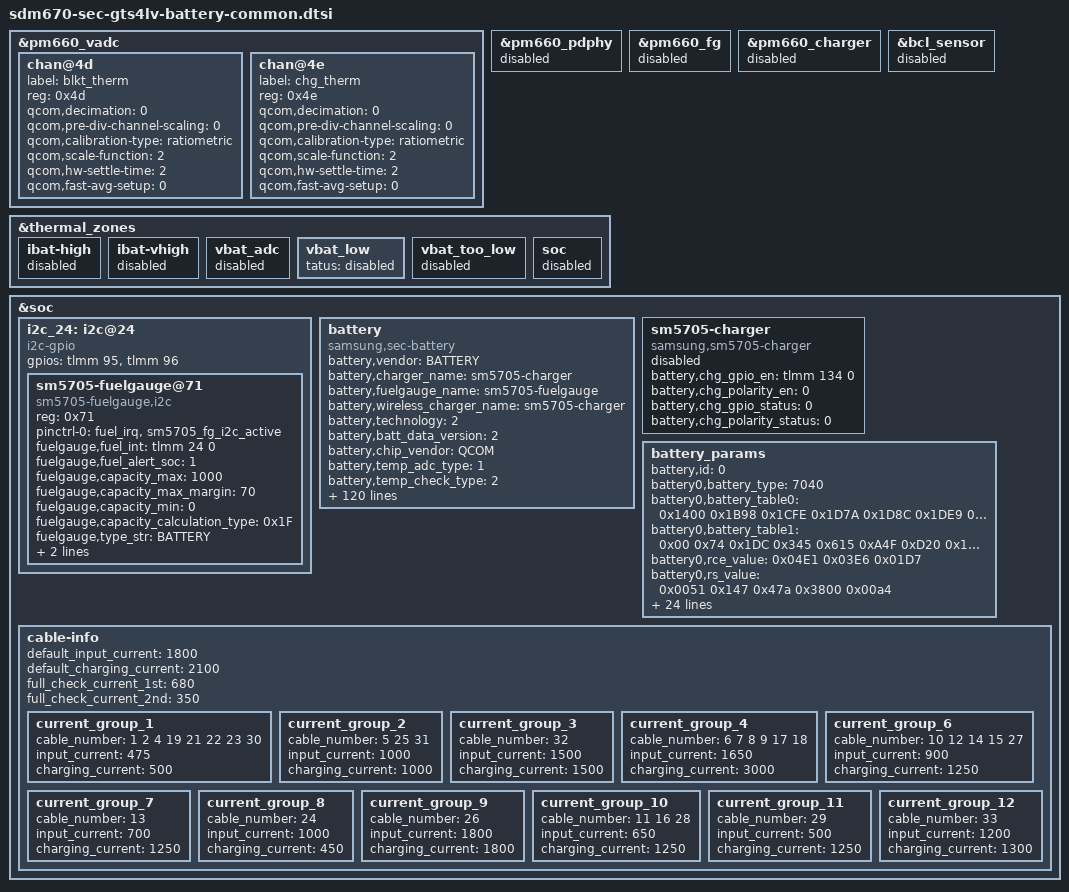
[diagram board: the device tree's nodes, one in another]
/* Copyright (c) 2014, The Linux Foundation. All rights reserved.
 *
 * This program is free software; you can redistribute it and/or modify
 * it under the terms of the GNU General Public License version 2 and
 * only version 2 as published by the Free Software Foundation.
 *
 * This program is distributed in the hope that it will be useful,
 * but WITHOUT ANY WARRANTY; without even the implied warranty of
 * MERCHANTABILITY or FITNESS FOR A PARTICULAR PURPOSE.  See the
 * GNU General Public License for more details.
 */

&pm660_vadc {
	chan@4d { /* AMUX_1 */
			label = "blkt_therm";
			reg = <0x4d>;
			qcom,decimation = <0>;
			qcom,pre-div-channel-scaling = <0>;
			qcom,calibration-type = "ratiometric";
			qcom,scale-function = <2>;
			qcom,hw-settle-time = <2>;
			qcom,fast-avg-setup = <0>;
		};

		chan@4e { /* AMUX_2 */
			label = "chg_therm";
			reg = <0x4e>;
			qcom,decimation = <0>;
			qcom,pre-div-channel-scaling = <0>;
			qcom,calibration-type = "ratiometric";
			qcom,scale-function = <2>;
			qcom,hw-settle-time = <2>;
			qcom,fast-avg-setup = <0>;
		};
};

&pm660_pdphy {
		status = "disabled";
};

&pm660_fg {
		status = "disabled";
};

&pm660_charger {
		status = "disabled";
};

&bcl_sensor{
		status = "disabled";
};

/* remove nodes related bcl */
&thermal_zones {
	ibat-high {
		status = "disabled";
	};
	ibat-vhigh {
		status = "disabled";
	};
	vbat_adc {
		status = "disabled";
	};
	vbat_low {
		tatus = "disabled";
	};
	vbat_too_low {
		status = "disabled";
	};
	soc {
		status = "disabled";
	};
};

&soc {
	i2c_24: i2c@24 {
		compatible = "i2c-gpio";
		gpios = <&tlmm 95 0 /* sda */
			&tlmm 96 0 /* scl */
			>;
		#address-cells = <1>;
		#size-cells = <0>;

		sm5705-fuelgauge@71 {
			compatible = "sm5705-fuelgauge,i2c";
			reg = <0x71>;
			pinctrl-names = "default";
			pinctrl-0 = <&fuel_irq &sm5705_fg_i2c_active>;
			fuelgauge,fuel_int = <&tlmm 24 0>;
			fuelgauge,fuel_alert_soc = <1>;
			fuelgauge,capacity_max = <1000>;
			fuelgauge,capacity_max_margin = <70>;
			fuelgauge,capacity_min = <0>;
			fuelgauge,capacity_calculation_type = <0x1F>;
			fuelgauge,type_str = "BATTERY";
			fuelgauge,model_type = <1>;
			fuelgauge,fg_log_enable = <1>;
		};
	};

};

&soc {
	battery {
		status = "okay";
		compatible = "samsung,sec-battery";
		battery,vendor = "BATTERY";
		battery,charger_name = "sm5705-charger";
		battery,fuelgauge_name = "sm5705-fuelgauge";
		battery,wireless_charger_name = "sm5705-charger";
		battery,technology = <2>; /* POWER_SUPPLY_TECHNOLOGY_LION */

		battery,batt_data_version = <2>;

		battery,chip_vendor = "QCOM";
		battery,temp_adc_type = <1>; /* SEC_BATTERY_ADC_TYPE_AP */

		battery,temp_check_type = <2>; /* SEC_BATTERY_TEMP_CHECK_TEMP */
		battery,chg_temp_check = <1>;
		battery,wpc_temp_check = <0>;
		battery,blkt_temp_check = <1>;

		battery,thermal_source = <2>; /* SEC_BATTERY_THERMAL_SOURCE_ADC */
		battery,usb_thermal_source = <0>; /* SEC_BATTERY_THERMAL_SOURCE_ADC */
		battery,chg_thermal_source = <1>;
		battery,wpc_thermal_source = <0>;
		battery,coil_thermal_source = <0>;
		battery,blkt_thermal_source = <1>;

		battery,polling_time = <10 30 30 30 3600>;

		battery,temp_table_adc = <1179 1378 1605 1880 2192 2589 3073 3598 4191 4865 5607 6432 7276 8214 9191 10150 11074 11957 12759 13486 14111 14621 15048>;
		battery,temp_table_data = <900 850 800 750 700 650 600 550 500 450 400 350 300 250 200 150 100 50 0 (-50) (-100) (-150) (-200)>;
		battery,chg_temp_table_adc = <1117 1306 1535 1811 2082 2599 2921 3432 4011 4662 5422 6283 7251 8054 9010 10047 10700 11781 12703 13421 14030 14556 14986>;
		battery,chg_temp_table_data = <900 850 800 750 700 650 600 550 500 450 400 350 300 250 200 150 100 50 0 (-50) (-100) (-150) (-200)>;
		battery,blkt_temp_table_adc = <1133 1322 1557 1834 2154 2557 2981 3456 4031 4700 5453 6313 7167 8101 9052 10029 10939 11825 12648 13356 14017 14501 14984>;
		battery,blkt_temp_table_data = <900 850 800 750 700 650 600 550 500 450 400 350 300 250 200 150 100 50 0 (-50) (-100) (-150) (-200)>;

		battery,adc_check_count = <5>;

		battery,cable_check_type = <4>; /* SEC_BATTERY_CABLE_CHECK_PSY */
		battery,cable_source_type = <1>; /* SEC_BATTERY_CABLE_SOURCE_EXTERNAL */
		battery,polling_type = <1>; /* SEC_BATTERY_MONITOR_ALARM */
		battery,monitor_initial_count = <0>;

		battery,battery_check_type = <0>; /* SEC_BATTERY_CHECK_NONE */
		battery,check_count = <0>;
		battery,check_adc_max = <1440>;
		battery,check_adc_min = <0>;

		battery,ovp_uvlo_check_type = <3>; /* SEC_BATTERY_OVP_UVLO_CHGPOLLING */

		battery,temp_check_count = <1>;
		battery,temp_highlimit_threshold_event = <800>;
		battery,temp_highlimit_recovery_event = <750>;
		battery,temp_high_threshold_event = <500>;
		battery,temp_high_recovery_event = <450>;
		battery,temp_low_threshold_event = <0>;
		battery,temp_low_recovery_event = <50>;
		battery,temp_highlimit_threshold_normal = <800>;
		battery,temp_highlimit_recovery_normal = <750>;
		battery,temp_high_threshold_normal = <500>;
		battery,temp_high_recovery_normal = <450>;
		battery,temp_low_threshold_normal = <0>;
		battery,temp_low_recovery_normal = <50>;
		battery,temp_highlimit_threshold_lpm = <800>;
		battery,temp_highlimit_recovery_lpm = <750>;
		battery,temp_high_threshold_lpm = <500>;
		battery,temp_high_recovery_lpm = <450>;
		battery,temp_low_threshold_lpm = <0>;
		battery,temp_low_recovery_lpm = <50>;
		battery,full_check_type = <2>; /* SEC_BATTERY_FULLCHARGED_FG_CURRENT */
		battery,full_check_type_2nd = <2>; /* SEC_BATTERY_FULLCHARGED_FG_CURRENT */
		battery,full_check_count = <1>;
		battery,chg_gpio_full_check = <0>;
		battery,chg_polarity_full_check = <1>;

		battery,chg_high_temp = <800>;
		battery,chg_high_temp_recovery = <770>;
		battery,chg_input_limit_current = <1000>;
		battery,chg_charging_limit_current = <1500>;

		battery,store_mode_afc_input_current = <700>;

		battery,mix_high_temp = <800>;
		battery,mix_high_chg_temp = <800>;
		battery,mix_high_temp_recovery = <770>;

		/* SEC_BATTERY_FULL_CONDITION_NOTIMEFULL |
		   SEC_BATTERY_FULL_CONDITION_VCELL */
		battery,full_condition_type = <9>;
		battery,full_condition_soc = <93>;
		battery,full_condition_vcell = <4250>;

		battery,recharge_check_count = <1>;
		battery,recharge_condition_type = <4>; /* SEC_BATTERY_RECHARGE_CONDITION_VCELL */
		battery,recharge_condition_soc = <98>;
		battery,recharge_condition_vcell = <4280>;

		battery,standard_curr = <3000>;
		battery,expired_time = <15000>;
		battery,recharging_expired_time = <5400>;
		battery,charging_reset_time = <0>;
		qcom,sec-battery-vadc = <&pm660_vadc>;

		battery,chg_float_voltage = <4350>;

		battery,pre_afc_work_delay = <2000>;
		battery,pre_afc_input_current = <500>;

		battery,swelling_high_temp_block = <410>;
		battery,swelling_high_temp_recov = <390>;
		battery,swelling_low_temp_block_1st = <150>;
		battery,swelling_low_temp_recov_1st = <200>;
		battery,swelling_low_temp_block_2nd = <50>;
		battery,swelling_low_temp_recov_2nd = <100>;
		battery,swelling_low_temp_current = <1200>;	/* 0.3C */ /* Max charge current 4000mA (0.8C) */
		battery,swelling_low_temp_topoff = <350>;	/* 0.05C */
		battery,swelling_high_temp_current = <1800>;	/* 0.45C */
		battery,swelling_high_temp_topoff = <350>;	/* 0.05C */
		battery,swelling_drop_float_voltage = <4150>;
		battery,swelling_high_rechg_voltage = <4000>;
		battery,swelling_low_rechg_voltage = <4000>;

		battery,siop_event_check_type = <1>;
		battery,siop_call_cv_current = <330>;
		battery,siop_call_cc_current = <330>;

		battery,siop_input_limit_current = <1500>;
		battery,siop_charging_limit_current = <1800>;
		battery,siop_hv_input_limit_current = <1500>;
		battery,siop_hv_charging_limit_current = <1800>;

		battery,ttf_hv_charge_current = <2645>;
		battery,ttf_pogo_charge_current = <1042>;

		battery,ttf_capacity = <6579>;
		battery,cv_data = <
				2691	811	2340
				2582	819	2280
				2485	826	2220
				2374	833	2160
				2278	839	2100
				2181	845	2040
				2095	852	1980
				2027	857	1920
				1918	862	1860
				1865	867	1800
				1779	872	1740
				1706	876	1680
				1614	881	1620
				1575	885	1560
				1492	889	1500
				1435	893	1440
				1388	897	1380
				1327	901	1320
				1275	905	1260
				1224	908	1200
				1181	911	1140
				1134	914	1080
				1084	917	1020
				1035	920	960
				990		922	900
				958		925	840
				943		928	780
				881		930	720
				828		932	660
				794		935	600
				791		936	540
				758		938	480
				722		940	420
				700		942	360
				670		944	300
				633		946	240
				615		948	180
				605		960	120
				579		980	60
				554		1000	0
					>;

		/* cycle, chg_float_voltage, recharge_condition_vcell, full_condition_vcell, full_condition_soc */
		battery,age_data = <0 4350 4280 4250 93
				300 4330 4260 4225 92
				400 4310 4240 4212 91
				700 4290 4220 4187 90
				1000 4240 4170 4137 89>;

		battery,pd_charging_charge_power = <15000>;
		battery,max_input_voltage = <9000>; /* mV */
		battery,max_input_current = <3000>;  /* mA */
		battery,max_charging_current = <3000>;

		battery,enable_sysovlo_irq;

		battery,battery_full_capacity = <7040>; /* battery capacity */
		battery,cisd_qh_current_low_thr = <190>;
		battery,cisd_qh_current_high_thr = <210>;
		battery,cisd_qh_vfsoc_thr = <100000>; /* 0.001% */
		/* disable Vbat ovp dettection */
		battery,cisd_max_voltage_thr = <5000>; /* batttery ovp dettection voltage */
		battery,cisd_alg_index = <7>;
		battery,full_chg_current_margin = <0>;

		battery,ignore_cisd_index = <0 960>;
		battery,ignore_cisd_index_d = <0 120>;
	};
	
	sm5705-charger {
		status = "disable";
		compatible = "samsung,sm5705-charger";
		battery,chg_gpio_en = <&tlmm 134 0>;
		battery,chg_polarity_en = <0>;
		battery,chg_gpio_status = <0>;
		battery,chg_polarity_status = <0>;
	};
	
	battery_params {
		battery,id = <0>; /* -1 means auto, detected by F/G */
		battery0,battery_type = <7040>; /* 4200 4350 4400 */
		battery0,battery_table0 = <0x1400 0x1B98 0x1CFE 0x1D7A 0x1D8C 0x1DE9 0x1E0C 0x1E41 0x1EF0 0x1EF0 0x1F6A 0x1FF8 0x207F 0x20D6 0x2216 0x2400>;
		battery0,battery_table1 = <0x00 0x74 0x1DC 0x345 0x615 0xA4F 0xD20 0x1159 0x1E05 0x1E05 0x20D6 0x2677 0x2948 0x2C19 0x33B3 0x33CE>;
		battery0,rce_value = <0x04E1 0x03E6 0x01D7>;
		battery0,rs_value = <0x0051 0x147 0x47a 0x3800 0x00a4>; /*rs p_mix_factor n_mix_factor max min*/
		battery0,misc = <0x0060>;
		battery0,topoff_soc = <0 3 350>; /*disable soc current*/
		battery0,vit_period = <0x3506>;
		battery0,dtcd_value = <0x1>;
		battery0,volt_cal = <0x8000>;
		battery0,curr_offset = <1 0x0000>; /*en_auto offset*/
		battery0,p_curr_cal = <0x009D>;
		battery0,n_curr_cal = <0x00A3>;
		battery0,mix_value = <0x0503 0x0004>; /*mix_rate init_blank*/
		battery0,temp_std = <25>;
		battery0,temp_cal = <1 6 1 11 (-1) 1 6 1 9 1>; /* en_h, p_de, p_fa, n_de, n_fa, en_l, p_de, p_fa, n_de, n_fa, */
		battery0,ext_temp_cal = <1 3 0 3 1 1 2 3 2 3>; /* en_h, p_de, p_fa, n_de, n_fa, en_l, p_de, p_fa, n_de, n_fa, */
		battery0,temp_volcal = <1 15 1>; /* en, temp, cal */
		battery0,temp_offset = <1 11 1 1 8 (-1)>; /* en_high level offset en_low level offset */
		battery0,cycle_cfg = <7 1 3>; /*high_limit low_limit cntl*/
		battery0,curr_lcal = <0 0x8888 0x8888 0x8888>;
		battery0,tem_poff = <3380 50 3320 50>;
		battery0,v_offset_cancel = <1 0 100 10>; /* en_p, en_n, level, mohm */
		battery0,v_alarm = <3000>;
		battery0,v_max_table = <0x2216 0x21EE 0x21C6 0x219E 0x213B>;
		battery0,q_max_table = <0x33B3 0x32C7 0x31DB 0x30EF 0x2EA2>;

		battery0,data_ver = <0x04>;
	};

/* sec_battery_cable
 *   0	UNKNOWN,
 *   1	NONE,
 *   2	PREPARE_TA,
 *   3	TA,
 *   4	USB,
 *   5	USB_CDP,
 *   6	9V_TA,
 *   7	9V_ERR,
 *   8	9V_UNKNOWN,
 *   9	12V_TA,
 *  10	WIRELESS,
 *  11	HV_WIRELESS,
 *  12	PMA_WIRELESS,
 *  13	WIRELESS_PACK,
 *  14	WIRELESS_PACK_TA,
 *  15	WIRELESS_STAND,
 *  16	WIRELESS_HV_STAND,
 *  17	QC20,
 *  18	QC30,
 *  19	PDIC,
 *  20	UARTOFF,
 *  21	OTG,
 *  22	LAN_HUB,
 *  23	POWER_SHARING,
 *  24	HMT_CONNECTED,
 *  25	HMT_CHARGE,
 *  26	HV_TA_CHG_LIMIT,
 *  27	WIRELESS_VEHICLE,
 *  28	WIRELESS_HV_VEHICLE,
 *  29	PREPARE_WIRELESS_HV,
 *  30  TIMEOUT,
 *  31  SMART_OTG,
 *  32  SMART_NOTG,
 *  33	CABLE_MAX,
 */
	cable-info {
		default_input_current = <1800>;
		default_charging_current = <2100>;
		full_check_current_1st = <680>;
		full_check_current_2nd = <350>;

		current_group_1 {
			cable_number = <1 2 4 19 21 22 23 30>;
			input_current = <475>;
			charging_current = <500>;
		};
		current_group_2 {
			cable_number = <5 25 31>;
			input_current = <1000>;
			charging_current = <1000>;
		};
		current_group_3 {
			cable_number = <32>;
			input_current = <1500>;
			charging_current = <1500>;
		};
		current_group_4 {
			cable_number = <6 7 8 9 17 18>;
			input_current = <1650>;
			charging_current = <3000>;
		};
		current_group_6 {
			cable_number = <10 12 14 15 27>;
			input_current = <900>;
			charging_current = <1250>;
		};
		current_group_7 {
			cable_number = <13>;
			input_current = <700>;
			charging_current = <1250>;
		};
		current_group_8 {
			cable_number = <24>;
			input_current = <1000>;
			charging_current = <450>;
		};
		current_group_9 {
			cable_number = <26>;
			input_current = <1800>;
			charging_current = <1800>;
		};
		current_group_10 {
			cable_number = <11 16 28>;
			input_current = <650>;
			charging_current = <1250>;
		};
		current_group_11 {
			cable_number = <29>;
			input_current = <500>;
			charging_current = <1250>;
		};
		current_group_12 {
			cable_number = <33>;
			input_current = <1200>;
			charging_current = <1300>;
		};
	};
};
